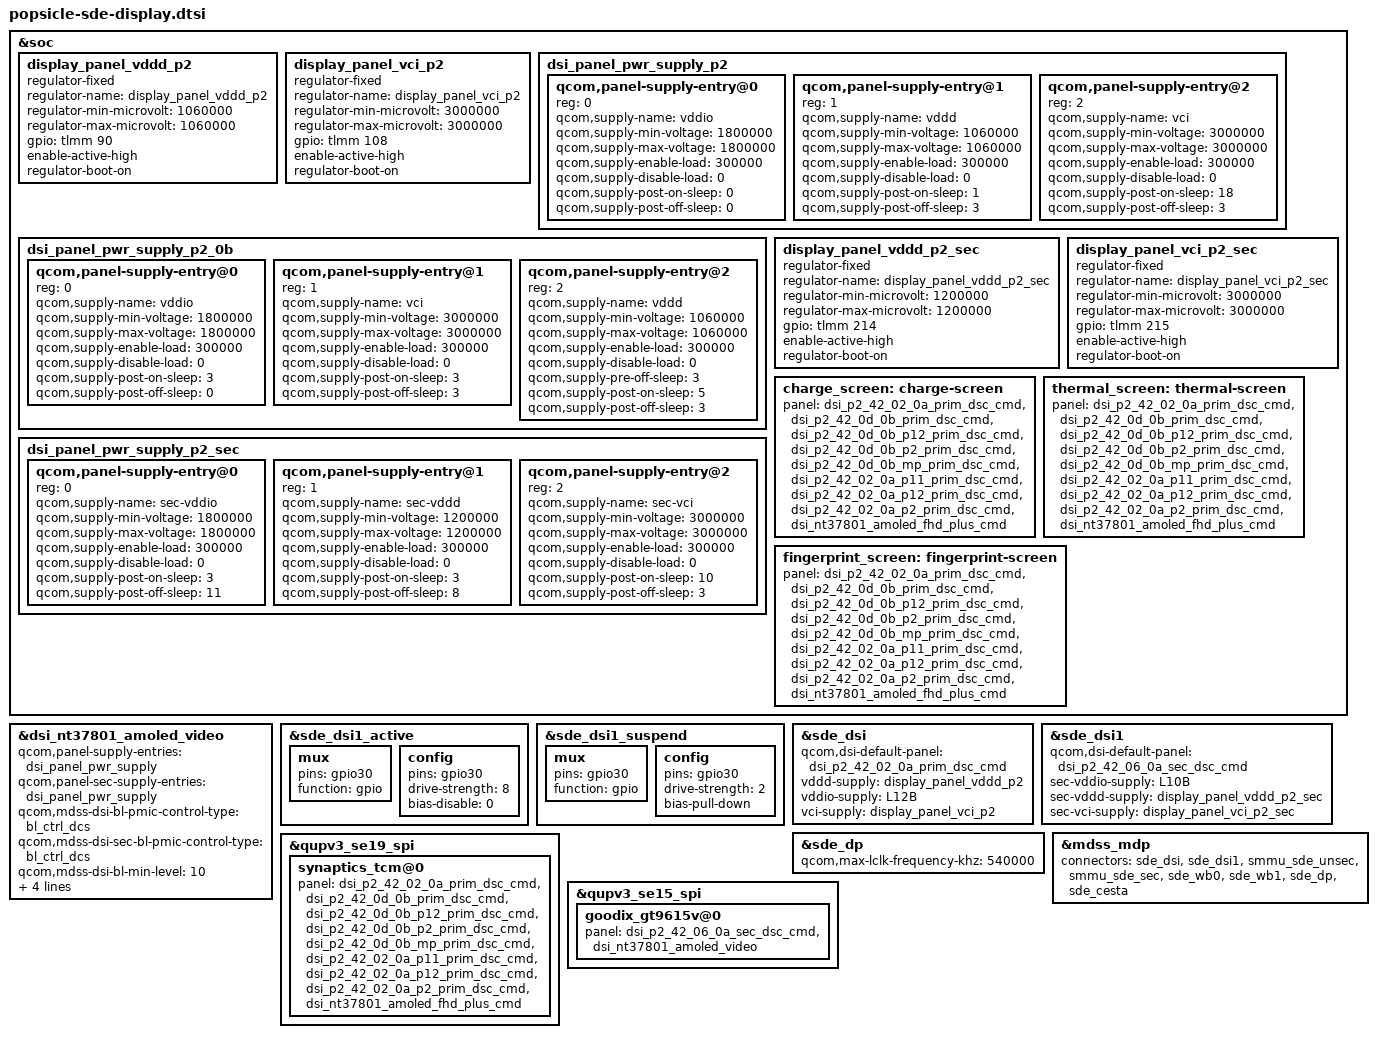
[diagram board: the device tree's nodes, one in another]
#include "canoe-sde-display.dtsi"
#include "dsi-panel-p2-42-02-0a-prim-dsc-cmd.dtsi"
#include "dsi-panel-p2-42-02-0a-p11-prim-dsc-cmd.dtsi"
#include "dsi-panel-p2-42-02-0a-p12-prim-dsc-cmd.dtsi"
#include "dsi-panel-p2-42-02-0a-p2-prim-dsc-cmd.dtsi"
#include "dsi-panel-p2-42-0d-0b-prim-dsc-cmd.dtsi"
#include "dsi-panel-p2-42-0d-0b-p12-prim-dsc-cmd.dtsi"
#include "dsi-panel-p2-42-0d-0b-p2-prim-dsc-cmd.dtsi"
#include "dsi-panel-p2-42-0d-0b-mp-prim-dsc-cmd.dtsi"
#include "dsi-panel-p2-42-06-0a-sec-dsc-cmd.dtsi"

&soc {
	display_panel_vddd_p2: display_panel_vddd_p2 {
		compatible = "regulator-fixed";
		regulator-name = "display_panel_vddd_p2";
		regulator-min-microvolt = <1060000>;
		regulator-max-microvolt = <1060000>;
		gpio = <&tlmm 90 0>;
		enable-active-high;
		regulator-boot-on;
	};
	display_panel_vci_p2: display_panel_vci_p2 {
		compatible = "regulator-fixed";
		regulator-name = "display_panel_vci_p2";
		regulator-min-microvolt = <3000000>;
		regulator-max-microvolt = <3000000>;
		gpio = <&tlmm 108 0>;
		enable-active-high;
		regulator-boot-on;
	};

	dsi_panel_pwr_supply_p2: dsi_panel_pwr_supply_p2 {
		qcom,panel-supply-entry@0 {
			reg = <0>;
			qcom,supply-name = "vddio";
			qcom,supply-min-voltage = <1800000>;
			qcom,supply-max-voltage = <1800000>;
			qcom,supply-enable-load = <300000>;
			qcom,supply-disable-load = <0>;
			qcom,supply-post-on-sleep = <0>;
			qcom,supply-post-off-sleep = <0>;
		};
		qcom,panel-supply-entry@1 {
			reg = <1>;
			qcom,supply-name = "vddd";
			qcom,supply-min-voltage = <1060000>;
			qcom,supply-max-voltage = <1060000>;
			qcom,supply-enable-load = <300000>;
			qcom,supply-disable-load = <0>;
			qcom,supply-post-on-sleep = <1>;
			qcom,supply-post-off-sleep = <3>;
		};
		qcom,panel-supply-entry@2 {
			reg = <2>;
			qcom,supply-name = "vci";
			qcom,supply-min-voltage = <3000000>;
			qcom,supply-max-voltage = <3000000>;
			qcom,supply-enable-load = <300000>;
			qcom,supply-disable-load = <0>;
			qcom,supply-post-on-sleep = <18>;
			qcom,supply-post-off-sleep = <3>;
		};
	};
	dsi_panel_pwr_supply_p2_0b: dsi_panel_pwr_supply_p2_0b {
		qcom,panel-supply-entry@0 {
			reg = <0>;
			qcom,supply-name = "vddio";
			qcom,supply-min-voltage = <1800000>;
			qcom,supply-max-voltage = <1800000>;
			qcom,supply-enable-load = <300000>;
			qcom,supply-disable-load = <0>;
			qcom,supply-post-on-sleep = <3>;
			qcom,supply-post-off-sleep = <0>;
		};
		qcom,panel-supply-entry@1 {
			reg = <1>;
			qcom,supply-name = "vci";
			qcom,supply-min-voltage = <3000000>;
			qcom,supply-max-voltage = <3000000>;
			qcom,supply-enable-load = <300000>;
			qcom,supply-disable-load = <0>;
			qcom,supply-post-on-sleep = <3>;
			qcom,supply-post-off-sleep = <3>;
		};
		qcom,panel-supply-entry@2 {
			reg = <2>;
			qcom,supply-name = "vddd";
			qcom,supply-min-voltage = <1060000>;
			qcom,supply-max-voltage = <1060000>;
			qcom,supply-enable-load = <300000>;
			qcom,supply-disable-load = <0>;
			qcom,supply-pre-off-sleep = <3>;
			qcom,supply-post-on-sleep = <5>;
			qcom,supply-post-off-sleep = <3>;
		};
	};
	display_panel_vddd_p2_sec: display_panel_vddd_p2_sec {
		compatible = "regulator-fixed";
		regulator-name = "display_panel_vddd_p2_sec";
		regulator-min-microvolt = <1200000>;
		regulator-max-microvolt = <1200000>;
		gpio = <&tlmm 214 0>;
		enable-active-high;
		regulator-boot-on;
	};
	display_panel_vci_p2_sec: display_panel_vci_p2_sec {
		compatible = "regulator-fixed";
		regulator-name = "display_panel_vci_p2_sec";
		regulator-min-microvolt = <3000000>;
		regulator-max-microvolt = <3000000>;
		gpio = <&tlmm 215 0>;
		enable-active-high;
		regulator-boot-on;
	};
	dsi_panel_pwr_supply_p2_sec: dsi_panel_pwr_supply_p2_sec {
		qcom,panel-supply-entry@0 {
			reg = <0>;
			qcom,supply-name = "sec-vddio";
			qcom,supply-min-voltage = <1800000>;
			qcom,supply-max-voltage = <1800000>;
			qcom,supply-enable-load = <300000>;
			qcom,supply-disable-load = <0>;
			qcom,supply-post-on-sleep = <3>;
			qcom,supply-post-off-sleep = <11>;
		};
		qcom,panel-supply-entry@1 {
			reg = <1>;
			qcom,supply-name = "sec-vddd";
			qcom,supply-min-voltage = <1200000>;
			qcom,supply-max-voltage = <1200000>;
			qcom,supply-enable-load = <300000>;
			qcom,supply-disable-load = <0>;
			qcom,supply-post-on-sleep = <3>;
			qcom,supply-post-off-sleep = <8>;
		};
		qcom,panel-supply-entry@2 {
			reg = <2>;
			qcom,supply-name = "sec-vci";
			qcom,supply-min-voltage = <3000000>;
			qcom,supply-max-voltage = <3000000>;
			qcom,supply-enable-load = <300000>;
			qcom,supply-disable-load = <0>;
			qcom,supply-post-on-sleep = <10>;
			qcom,supply-post-off-sleep = <3>;
		};
	};
};
&dsi_nt37801_amoled_video {
       qcom,panel-supply-entries = <&dsi_panel_pwr_supply>;
       qcom,panel-sec-supply-entries = <&dsi_panel_pwr_supply>;
       qcom,mdss-dsi-bl-pmic-control-type = "bl_ctrl_dcs";
       qcom,mdss-dsi-sec-bl-pmic-control-type = "bl_ctrl_dcs";
       qcom,mdss-dsi-bl-min-level = <10>;
       qcom,mdss-dsi-bl-max-level = <4095>;
       qcom,mdss-brightness-max-level = <8191>;
       qcom,mdss-dsi-bl-inverted-dbv;
       qcom,platform-sec-reset-gpio = <&tlmm 30 0>;
};
&sde_dsi1_active {
	mux {
		pins = "gpio30";
		function = "gpio";
	};

	config {
		pins = "gpio30";
		drive-strength = <8>;   /* 8 mA */
		bias-disable = <0>;   /* no pull */
	};
};

&sde_dsi1_suspend {
	mux {
		pins = "gpio30";
		function = "gpio";
	};

	config {
		pins = "gpio30";
		drive-strength = <2>;   /* 2 mA */
		bias-pull-down;         /* PULL DOWN */
	};
};

&sde_dsi {
	qcom,dsi-default-panel = <&dsi_p2_42_02_0a_prim_dsc_cmd>;
	vddd-supply = <&display_panel_vddd_p2>;
	vddio-supply = <&L12B>;
	vci-supply = <&display_panel_vci_p2>;

	/delete-property/ tvdd-supply;
};

&sde_dsi1 {
	qcom,dsi-default-panel = <&dsi_p2_42_06_0a_sec_dsc_cmd>;
	sec-vddio-supply = <&L10B>;
	sec-vddd-supply = <&display_panel_vddd_p2_sec>;
	sec-vci-supply = <&display_panel_vci_p2_sec>;

	/delete-property/ tvdd-supply;
	/delete-property/ vddd-supply;
	/delete-property/ vddio-supply;
	/delete-property/ vci-supply;
};

&sde_dp {
	qcom,max-lclk-frequency-khz = <540000>;
	status = "ok";
};

&mdss_mdp {
	connectors = <&sde_dsi &sde_dsi1 &smmu_sde_unsec &smmu_sde_sec &sde_wb0 &sde_wb1 &sde_dp &sde_cesta>;
};

&qupv3_se19_spi {
	synaptics_tcm@0 {
		panel = <&dsi_p2_42_02_0a_prim_dsc_cmd
			&dsi_p2_42_0d_0b_prim_dsc_cmd
			&dsi_p2_42_0d_0b_p12_prim_dsc_cmd
			&dsi_p2_42_0d_0b_p2_prim_dsc_cmd
			&dsi_p2_42_0d_0b_mp_prim_dsc_cmd
			&dsi_p2_42_02_0a_p11_prim_dsc_cmd
			&dsi_p2_42_02_0a_p12_prim_dsc_cmd
			&dsi_p2_42_02_0a_p2_prim_dsc_cmd
			&dsi_nt37801_amoled_fhd_plus_cmd>;
	};
};

&qupv3_se15_spi {
	goodix_gt9615v@0 {
		panel = <&dsi_p2_42_06_0a_sec_dsc_cmd
			&dsi_nt37801_amoled_video>;
	};
};

&soc {
	charge_screen: charge-screen {
		panel = <&dsi_p2_42_02_0a_prim_dsc_cmd
			&dsi_p2_42_0d_0b_prim_dsc_cmd
			&dsi_p2_42_0d_0b_p12_prim_dsc_cmd
			&dsi_p2_42_0d_0b_p2_prim_dsc_cmd
			&dsi_p2_42_0d_0b_mp_prim_dsc_cmd
			&dsi_p2_42_02_0a_p11_prim_dsc_cmd
			&dsi_p2_42_02_0a_p12_prim_dsc_cmd
			&dsi_p2_42_02_0a_p2_prim_dsc_cmd
			&dsi_nt37801_amoled_fhd_plus_cmd>;
	};
	thermal_screen: thermal-screen {
		panel = <&dsi_p2_42_02_0a_prim_dsc_cmd
			&dsi_p2_42_0d_0b_prim_dsc_cmd
			&dsi_p2_42_0d_0b_p12_prim_dsc_cmd
			&dsi_p2_42_0d_0b_p2_prim_dsc_cmd
			&dsi_p2_42_0d_0b_mp_prim_dsc_cmd
			&dsi_p2_42_02_0a_p11_prim_dsc_cmd
			&dsi_p2_42_02_0a_p12_prim_dsc_cmd
			&dsi_p2_42_02_0a_p2_prim_dsc_cmd
			&dsi_nt37801_amoled_fhd_plus_cmd>;
	};
	fingerprint_screen: fingerprint-screen {
		panel = <&dsi_p2_42_02_0a_prim_dsc_cmd
			&dsi_p2_42_0d_0b_prim_dsc_cmd
			&dsi_p2_42_0d_0b_p12_prim_dsc_cmd
			&dsi_p2_42_0d_0b_p2_prim_dsc_cmd
			&dsi_p2_42_0d_0b_mp_prim_dsc_cmd
			&dsi_p2_42_02_0a_p11_prim_dsc_cmd
			&dsi_p2_42_02_0a_p12_prim_dsc_cmd
			&dsi_p2_42_02_0a_p2_prim_dsc_cmd
			&dsi_nt37801_amoled_fhd_plus_cmd>;
	};
};
